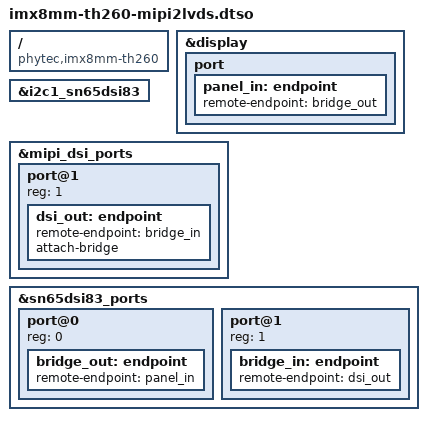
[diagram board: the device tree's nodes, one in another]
// SPDX-License-Identifier: GPL-2.0
/*
 * Copyright (C) 2022 PHYTEC Messtechnik GmbH
 * Author: Teresa Remmet <t.remmet@phytec.de>
 *
 * Overlay for SoMs as DUT with a MIPI2LVDS converter mounted.
 */

/dts-v1/;
/plugin/;

/ {
	compatible = "phytec,imx8mm-th260";
};

&display {
	port {
		panel_in: endpoint {
			remote-endpoint = <&bridge_out>;
		};
	};
};

&i2c1_sn65dsi83 {
	status = "okay";
};

&mipi_dsi_ports {

	#address-cells = <0x1>;
	#size-cells = <0x0>;

	port@1 {
		reg = <1>;
		dsi_out: endpoint {
			remote-endpoint = <&bridge_in>;
			attach-bridge;
		};
	};
};

&sn65dsi83_ports {
	#address-cells = <1>;
	#size-cells = <0>;

	port@0 {
		reg = <0>;

		bridge_out: endpoint {
			remote-endpoint = <&panel_in>;
		};
	};

	port@1 {
		reg = <1>;

		bridge_in: endpoint {
			remote-endpoint = <&dsi_out>;
		};
	};
};
